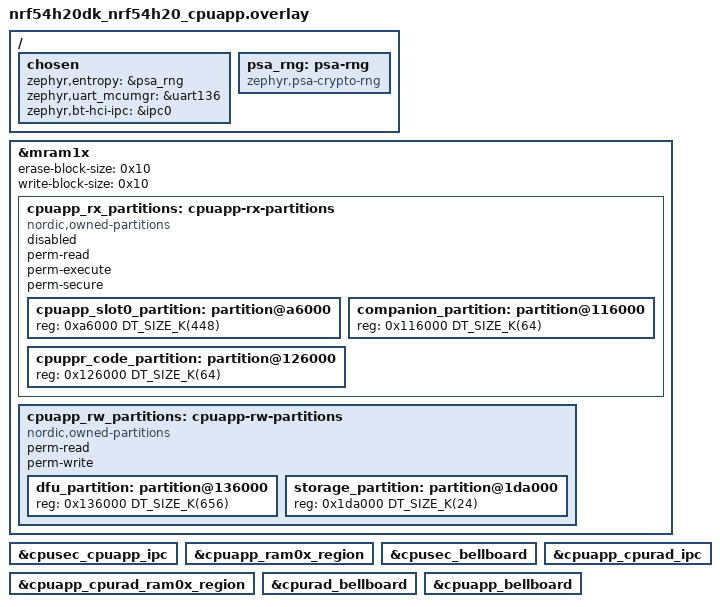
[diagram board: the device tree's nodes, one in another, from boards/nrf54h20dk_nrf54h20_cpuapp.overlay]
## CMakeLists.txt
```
#
# Copyright (c) 2023 Nordic Semiconductor ASA
#
# SPDX-License-Identifier: LicenseRef-Nordic-5-Clause
#

cmake_minimum_required(VERSION 3.13.1)

find_package(Zephyr REQUIRED HINTS $ENV{ZEPHYR_BASE})

project(suit_smp_transfer)

target_sources(app PRIVATE src/main.c)
target_sources_ifdef(CONFIG_MCUMGR_TRANSPORT_BT app PRIVATE src/bluetooth.c)
```

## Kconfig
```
#
# Copyright (c) 2023 Nordic Semiconductor ASA
#
# SPDX-License-Identifier: LicenseRef-Nordic-5-Clause
#

config APP_VERSION
	int "Application version"
	default 1

config SUIT_ENVELOPE_SEQUENCE_NUM
	default APP_VERSION

config SUIT_SECDOM_UPDATE_LOG
	bool "Enable Secure Domain logs in update candidate"
	default n
	select EXPERIMENTAL

config SUIT_SECDOM_EXTMEM_SUPPORT
	bool "Enable external flash support in SDFW"
	select EXPERIMENTAL

config SUIT_BUILD_FLASH_COMPANION
	bool "Enable build of the flash companion firmware"
	select EXPERIMENTAL

config SUIT_EXTERNAL_MEMORY_SUPPORT
	bool "Enable options needed to use external flash during DFU"
	depends on SUIT_DFU_CANDIDATE_PROCESSING_FULL
	imply SUIT_SECDOM_EXTMEM_SUPPORT
	imply SUIT_BUILD_FLASH_COMPANION
	imply SUIT_STREAM_SOURCE_FLASH
	select EXPERIMENTAL

source "Kconfig.zephyr"
```

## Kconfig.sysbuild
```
source "${ZEPHYR_BASE}/share/sysbuild/Kconfig"

if SUIT_BUILD_RECOVERY

choice SUIT_RECOVERY_APPLICATION
	prompt "Select SUIT recovery application"
	# default SUIT_RECOVERY_APPLICATION_DEFAULT

config SUIT_RECOVERY_APPLICATION_APPCORE
	bool "Use the appcore recovery application"
	help
	  Use the sample appcore recovery application.

endchoice

config SUIT_RECOVERY_APPLICATION_PATH
	string
	default "${ZEPHYR_NRF_MODULE_DIR}/samples/suit/recovery_appcore" if SUIT_RECOVERY_APPLICATION_APPCORE
	help
	  Source directory of the SUIT recovery appcore only application.

endif # SUIT_BUILD_RECOVERY
```

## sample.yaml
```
#
# Copyright (c) 2023 Nordic Semiconductor ASA
#
# SPDX-License-Identifier: LicenseRef-Nordic-5-Clause
#
# dummy change for triggers

sample:
  name: SUIT update through SMP sample
  description: Sample application that updates firmware using SUIT and SMP protocol
common:
  platform_allow: nrf54h20dk/nrf54h20/cpuapp
  build_only: true
  sysbuild: true
tests:
  sample.suit.smp_transfer:
    tags: suit ci_samples_suit

  sample.suit.smp_transfer.bt:
    extra_args:
      - FILE_SUFFIX=bt
    tags: suit bluetooth ci_samples_suit

  sample.suit.smp_transfer.full:
    extra_configs:
      - CONFIG_SUIT_DFU_CANDIDATE_PROCESSING_FULL=y
    tags: suit ci_samples_suit

  sample.suit.smp_transfer.full.bt:
    extra_args:
      - FILE_SUFFIX=bt
    extra_configs:
      - CONFIG_SUIT_DFU_CANDIDATE_PROCESSING_FULL=y
    tags: suit bluetooth ci_samples_suit

  sample.suit.smp_transfer.full.extflash:
    extra_args:
      - FILE_SUFFIX=extflash
    tags: suit ci_samples_suit

  sample.suit.smp_transfer.recovery:
    extra_args:
      - FILE_SUFFIX=bt
      - SB_CONFIG_SUIT_BUILD_RECOVERY=y
    extra_configs:
      - CONFIG_SUIT_DFU_CANDIDATE_PROCESSING_FULL=y
    tags: suit bluetooth ci_samples_suit

  sample.suit.smp_transfer.full.extflash.bt:
    extra_args:
      - FILE_SUFFIX=extflash
      - OVERLAY_CONFIG="sysbuild/smp_transfer_bt.conf"
      - SB_OVERLAY_CONFIG="sysbuild_bt.conf"
    tags: suit bluetooth ci_samples_suit

  sample.suit.smp_transfer.full.extflash.extracted_cache:
    extra_args:
      - FILE_SUFFIX=extflash
      - SUIT_DFU_CACHE_PARTITION_1_EB_SIZE=4096
    extra_configs:
      - CONFIG_SUIT_DFU_CACHE_EXTRACT_IMAGE=y
    tags: suit ci_samples_suit

  sample.suit.smp_transfer.full.extflash.bt.extracted_cache:
    extra_args:
      - FILE_SUFFIX=extflash
      - OVERLAY_CONFIG="sysbuild/smp_transfer_bt.conf"
      - SB_OVERLAY_CONFIG="sysbuild_bt.conf"
      - SUIT_DFU_CACHE_PARTITION_1_EB_SIZE=4096
    extra_configs:
      - CONFIG_SUIT_DFU_CACHE_EXTRACT_IMAGE=y
      - hci_ipc_CONFIG_SUIT_DFU_CACHE_EXTRACT_IMAGE=y
    tags: suit bluetooth ci_samples_suit
```

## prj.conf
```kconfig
#
# Copyright (c) 2023 Nordic Semiconductor ASA
#
# SPDX-License-Identifier: LicenseRef-Nordic-5-Clause
#

# Enable DK LED library
CONFIG_DK_LIBRARY=y

# Enable mcumgr
CONFIG_NET_BUF=y
CONFIG_ZCBOR=y
CONFIG_MCUMGR=y
CONFIG_MCUMGR_SMP_LEGACY_RC_BEHAVIOUR=y
CONFIG_CRC=y

# Enable the serial mcumgr transport
CONFIG_SERIAL=y
CONFIG_CONSOLE=y
CONFIG_BASE64=y
CONFIG_MCUMGR_TRANSPORT_UART=y

# Enable SUIT services
CONFIG_SUIT=y
CONFIG_MGMT_SUITFU=y
CONFIG_FLASH=y

# Enable SUIT envelope creation
CONFIG_SUIT_ENVELOPE=y

# Extended SUIT commands over USER group
CONFIG_MGMT_SUITFU_GRP_SUIT=y
```

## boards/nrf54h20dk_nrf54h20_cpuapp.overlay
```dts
/*
 * Copyright (c) 2023 Nordic Semiconductor ASA
 *
 * SPDX-License-Identifier: LicenseRef-Nordic-5-Clause
 */

/ {
	chosen {
		zephyr,entropy = &psa_rng;
		zephyr,uart_mcumgr = &uart136;
		zephyr,bt-hci-ipc = &ipc0;
	};

	psa_rng: psa-rng {
		compatible = "zephyr,psa-crypto-rng";
		status = "okay";
	};
};

/delete-node/ &cpuapp_rx_partitions;
/delete-node/ &cpuapp_rw_partitions;

&mram1x {
	erase-block-size = < 0x10 >;
	/* Hardcoded inside the soc_flash_nrf_mram.c (MRAM_WORD_SIZE) */
	write-block-size = < 0x10 >;

	cpuapp_rx_partitions: cpuapp-rx-partitions {
		compatible = "nordic,owned-partitions", "fixed-partitions";
		status = "disabled";
		perm-read;
		perm-execute;
		perm-secure;
		#address-cells = <1>;
		#size-cells = <1>;

		cpuapp_slot0_partition: partition@a6000 {
			reg = <0xa6000 DT_SIZE_K(448)>;
		};

		companion_partition: partition@116000 {
			reg = <0x116000 DT_SIZE_K(64)>;
		};

		cpuppr_code_partition: partition@126000 {
			reg = <0x126000 DT_SIZE_K(64)>;
		};
	};

	cpuapp_rw_partitions: cpuapp-rw-partitions {
		compatible = "nordic,owned-partitions", "fixed-partitions";
		status = "okay";
		perm-read;
		perm-write;
		#address-cells = < 0x1 >;
		#size-cells = < 0x1 >;

		dfu_partition: partition@136000 {
			reg = < 0x136000 DT_SIZE_K(656) >;
		};

		storage_partition: partition@1da000 {
			reg = < 0x1da000 DT_SIZE_K(24) >;
		};
	};
};

&cpusec_cpuapp_ipc {
	status = "okay";
};

&cpuapp_ram0x_region {
	status = "okay";
};

&cpusec_bellboard {
	status = "okay";
};

ipc0: &cpuapp_cpurad_ipc {
	status = "okay";
};

&cpuapp_cpurad_ram0x_region {
	status = "okay";
};

&cpurad_bellboard {
	status = "okay";
};

&cpuapp_bellboard {
	status = "okay";
};
```

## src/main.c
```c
/*
 * Copyright (c) 2023 Nordic Semiconductor ASA
 *
 * SPDX-License-Identifier: LicenseRef-Nordic-5-Clause
 */

#include <zephyr/kernel.h>
#include <dk_buttons_and_leds.h>
#ifdef CONFIG_MGMT_SUITFU
#include <suitfu_mgmt.h>
#endif /* CONFIG_MGMT_SUITFU */
#include <zephyr/storage/flash_map.h>
#include "common.h"

#ifdef CONFIG_SSF_SUIT_SERVICE_ENABLED
#include <sdfw/sdfw_services/suit_service.h>
#endif /* CONFIG_SSF_SUIT_SERVICE_ENABLED */

#define DFU_PARTITION_OFFSET  FIXED_PARTITION_OFFSET(dfu_partition)
#define DFU_PARTITION_SIZE    FIXED_PARTITION_SIZE(dfu_partition)
#define DFU_PARTITION_ADDRESS suit_plat_mem_nvm_ptr_get(DFU_PARTITION_OFFSET)

int main(void)
{
	int ret = dk_leds_init();

	if (ret) {
		printk("Cannot init LEDs (err: %d)\r\n", ret);
	}

	printk("Hello world from %s version: %d\r\n", CONFIG_BOARD, CONFIG_APP_VERSION);

#if (CONFIG_SSF_SUIT_SERVICE_ENABLED) && (CONFIG_APP_VERSION == 1) && (!CONFIG_MGMT_SUITFU)
	suit_plat_mreg_t update_candidate[] = {
		{
			.mem = DFU_PARTITION_ADDRESS,
			.size = DFU_PARTITION_SIZE,
		},
	};

	printk("Validate candidate: %p (0x%x)\r\n", update_candidate[0].mem,
	       update_candidate[0].size);
	bool dfu_partition_valid =
		suit_validate_candidate(update_candidate[0].mem, update_candidate[0].size);

	printk("DFU update candidate found in DFU partition: %d\r\n", dfu_partition_valid);
	if (dfu_partition_valid) {
		int ret = suit_trigger_update(update_candidate, ARRAY_SIZE(update_candidate));

		printk("DFU triggered with status: %d\r\n", ret);
	}
#endif

#ifdef CONFIG_MCUMGR_TRANSPORT_BT
	start_smp_bluetooth();
#endif

	while (1) {
		for (int i = 0; i < CONFIG_APP_VERSION; i++) {
			dk_set_led_on(DK_LED1);
			k_msleep(250);
			dk_set_led_off(DK_LED1);
			k_msleep(250);
		}

		k_msleep(5000);
	}

	return 0;
}
```
